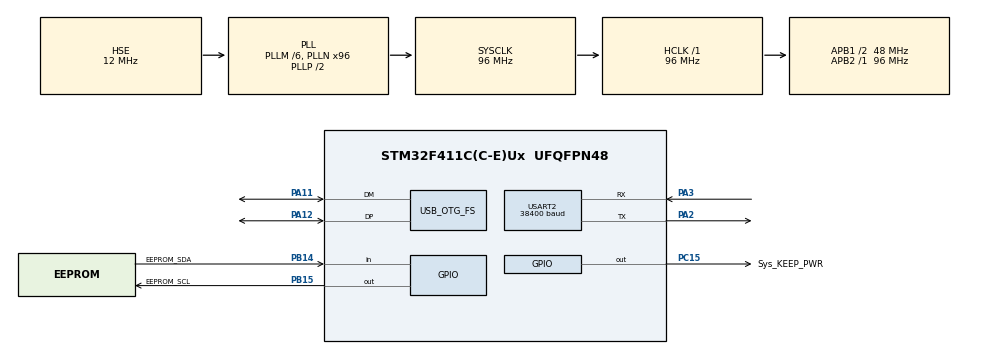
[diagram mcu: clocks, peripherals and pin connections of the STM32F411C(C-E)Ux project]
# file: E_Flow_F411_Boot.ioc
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Mcu.Family=STM32F4
Mcu.Name=STM32F411C(C-E)Ux
Mcu.Package=UFQFPN48
NVIC.OTG_FS_IRQn=true\:0\:0\:false\:false\:true\:false\:true\:true
NVIC.PriorityGroup=NVIC_PRIORITYGROUP_4
NVIC.TIM1_UP_TIM10_IRQn=true\:0\:0\:false\:false\:true\:false\:true\:true
NVIC.TimeBase=TIM1_UP_TIM10_IRQn
NVIC.TimeBaseIP=TIM1
PA11.Mode=Device_Only
PA11.Signal=USB_OTG_FS_DM
PA12.Mode=Device_Only
PA12.Signal=USB_OTG_FS_DP
PA13.Mode=Serial_Wire
PA13.Signal=SYS_JTMS-SWDIO
PA14.Mode=Serial_Wire
PA14.Signal=SYS_JTCK-SWCLK
PA2.Mode=Asynchronous
PA2.Signal=USART2_TX
PA3.Mode=Asynchronous
PA3.Signal=USART2_RX
PB14.GPIO_Label=EEPROM_SDA
PB14.Signal=GPIO_Input
PB15.GPIO_Label=EEPROM_SCL
PB15.Signal=GPIO_Output
PC15-OSC32_OUT.GPIO_Label=Sys_KEEP_PWR
PC15-OSC32_OUT.PinState=GPIO_PIN_SET
PC15-OSC32_OUT.Signal=GPIO_Output
PH0\ -\ OSC_IN.Mode=HSE-External-Oscillator
PH0\ -\ OSC_IN.Signal=RCC_OSC_IN
PH1\ -\ OSC_OUT.Mode=HSE-External-Oscillator
PH1\ -\ OSC_OUT.Signal=RCC_OSC_OUT
ProjectManager.HeapSize=0x400
ProjectManager.StackSize=0x800
ProjectManager.TargetToolchain=MDK-ARM V5.27
RCC.48MHZClocksFreq_Value=48000000
RCC.AHBFreq_Value=96000000
RCC.APB1CLKDivider=RCC_HCLK_DIV2
RCC.APB1Freq_Value=48000000
RCC.APB1TimFreq_Value=96000000
RCC.APB2Freq_Value=96000000
RCC.APB2TimFreq_Value=96000000
RCC.CortexFreq_Value=96000000
RCC.HCLKFreq_Value=96000000
RCC.HSE_VALUE=12000000
RCC.HSI_VALUE=16000000
RCC.LSE_VALUE=32768
RCC.PLLM=6
RCC.PLLN=96
RCC.SYSCLKFreq_VALUE=96000000
RCC.SYSCLKSource=RCC_SYSCLKSOURCE_PLLCLK
RCC.VCOOutputFreq_Value=192000000
USART2.BaudRate=38400
USART2.VirtualMode=VM_ASYNC
USB_DEVICE.CLASS_NAME_FS=MSC
USB_DEVICE.VirtualMode=Msc
USB_DEVICE.VirtualModeFS=Msc_FS
USB_OTG_FS.VirtualMode=Device_Only
VP_SYS_VS_tim1.Mode=TIM1
VP_USB_DEVICE_VS_USB_DEVICE_MSC_FS.Mode=MSC_FS
board=custom

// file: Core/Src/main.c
/* USER CODE BEGIN Header */
/**
  ******************************************************************************
  * @file           : main.c
  * @brief          : Main program body
  ******************************************************************************
  * @attention
  *
  * Copyright (c) 2023 STMicroelectronics.
  * All rights reserved.
  *
  * This software is licensed under terms that can be found in the LICENSE file
  * in the root directory of this software component.
  * If no LICENSE file comes with this software, it is provided AS-IS.
  *
  ******************************************************************************
  */
/* USER CODE END Header */
#include "main.h"
#include "usart.h"
#include "usb_device.h"
#include "gpio.h"

/* USER CODE BEGIN Includes */
#include "app_main.h"
/* USER CODE END Includes */

void SystemClock_Config(void);

int main(void)
{
  /* USER CODE BEGIN 1 */
	Before_HAL_Init();
  /* USER CODE END 1 */

  /* MCU Configuration--------------------------------------------------------*/

  /* Reset of all peripherals, Initializes the Flash interface and the Systick. */
  HAL_Init();

  /* Configure the system clock */
  SystemClock_Config();

  /* Initialize all configured peripherals */
  MX_GPIO_Init();
  MX_USART2_UART_Init();
//  MX_USB_DEVICE_Init();
  /* USER CODE BEGIN 2 */
	app_init();
  /* USER CODE END 2 */

  /* Infinite loop */
  /* USER CODE BEGIN WHILE */
  while (1)
  {
	  app_exec();
    /* USER CODE END WHILE */

  }
}

void SystemClock_Config(void)
{
  RCC_OscInitTypeDef RCC_OscInitStruct = {0};
  RCC_ClkInitTypeDef RCC_ClkInitStruct = {0};

  /** Configure the main internal regulator output voltage
  */
  __HAL_RCC_PWR_CLK_ENABLE();
  __HAL_PWR_VOLTAGESCALING_CONFIG(PWR_REGULATOR_VOLTAGE_SCALE1);

  /** Initializes the RCC Oscillators according to the specified parameters
  * in the RCC_OscInitTypeDef structure.
  */
  RCC_OscInitStruct.OscillatorType = RCC_OSCILLATORTYPE_HSE;
  RCC_OscInitStruct.HSEState = RCC_HSE_ON;
  RCC_OscInitStruct.PLL.PLLState = RCC_PLL_ON;
  RCC_OscInitStruct.PLL.PLLSource = RCC_PLLSOURCE_HSE;
  RCC_OscInitStruct.PLL.PLLM = 6;
  RCC_OscInitStruct.PLL.PLLN = 96;
  RCC_OscInitStruct.PLL.PLLP = RCC_PLLP_DIV2;
  RCC_OscInitStruct.PLL.PLLQ = 4;
  if (HAL_RCC_OscConfig(&RCC_OscInitStruct) != HAL_OK)
  {
    Error_Handler();
  }

  /** Initializes the CPU, AHB and APB buses clocks
  */
  RCC_ClkInitStruct.ClockType = RCC_CLOCKTYPE_HCLK|RCC_CLOCKTYPE_SYSCLK
                              |RCC_CLOCKTYPE_PCLK1|RCC_CLOCKTYPE_PCLK2;
  RCC_ClkInitStruct.SYSCLKSource = RCC_SYSCLKSOURCE_PLLCLK;
  RCC_ClkInitStruct.AHBCLKDivider = RCC_SYSCLK_DIV1;
  RCC_ClkInitStruct.APB1CLKDivider = RCC_HCLK_DIV2;
  RCC_ClkInitStruct.APB2CLKDivider = RCC_HCLK_DIV1;

  if (HAL_RCC_ClockConfig(&RCC_ClkInitStruct, FLASH_LATENCY_3) != HAL_OK)
  {
    Error_Handler();
  }
}

void HAL_TIM_PeriodElapsedCallback(TIM_HandleTypeDef *htim)
{
  if (htim->Instance == TIM1) {
    HAL_IncTick();
  }
}

void Error_Handler(void)
{
  __disable_irq();
  while (1)
  {
  }
}
